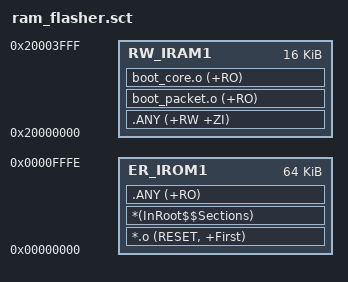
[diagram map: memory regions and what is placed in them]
; *************************************************************
; *** Scatter-Loading Description File generated by uVision ***
; *************************************************************

LR_IROM1 0x00000000 0x0000FFFF  {    ; load region size_region
  ER_IROM1 0x00000000 0x0000FFFF  {  ; load address = execution address
   *.o (RESET, +First)
   *(InRoot$$Sections)
   .ANY (+RO)
  }
  RW_IRAM1 0x20000000 0x00004000  {  ; RW data
   .ANY (+RW +ZI)
   boot_packet.o (+RO)
   boot_core.o (+RO)   
  }
}

